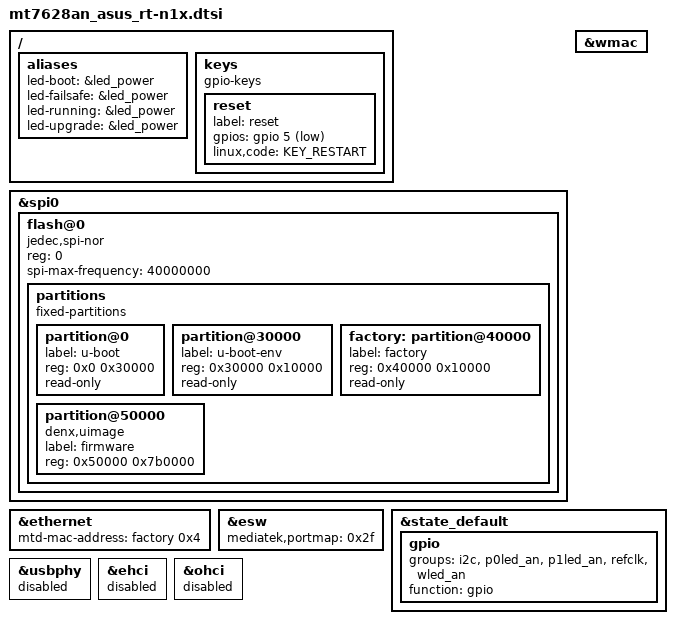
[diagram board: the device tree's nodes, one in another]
// SPDX-License-Identifier: GPL-2.0+

#include "mt7628an.dtsi"

#include <dt-bindings/gpio/gpio.h>
#include <dt-bindings/input/input.h>

/ {
	aliases {
		led-boot = &led_power;
		led-failsafe = &led_power;
		led-running = &led_power;
		led-upgrade = &led_power;
	};

	keys {
		compatible = "gpio-keys";

		reset {
			label = "reset";
			gpios = <&gpio 5 GPIO_ACTIVE_LOW>;
			linux,code = <KEY_RESTART>;
		};
	};
};

&spi0 {
	status = "okay";

	flash@0 {
		compatible = "jedec,spi-nor";
		reg = <0>;
		spi-max-frequency = <40000000>;

		partitions {
			compatible = "fixed-partitions";
			#address-cells = <1>;
			#size-cells = <1>;

			partition@0 {
				label = "u-boot";
				reg = <0x0 0x30000>;
				read-only;
			};

			partition@30000 {
				label = "u-boot-env";
				reg = <0x30000 0x10000>;
				read-only;
			};

			factory: partition@40000 {
				label = "factory";
				reg = <0x40000 0x10000>;
				read-only;
			};

			partition@50000 {
				compatible = "denx,uimage";
				label = "firmware";
				reg = <0x50000 0x7b0000>;
			};
		};
	};
};

&ethernet {
	mtd-mac-address = <&factory 0x4>;
};

&esw {
	mediatek,portmap = <0x2f>;
};

&wmac {
	status = "okay";
};

&state_default {
	gpio {
		groups = "i2c", "p0led_an", "p1led_an", "refclk", "wled_an";
		function = "gpio";
	};
};

&usbphy {
	status = "disabled";
};

&ehci {
	status = "disabled";
};

&ohci {
	status = "disabled";
};
